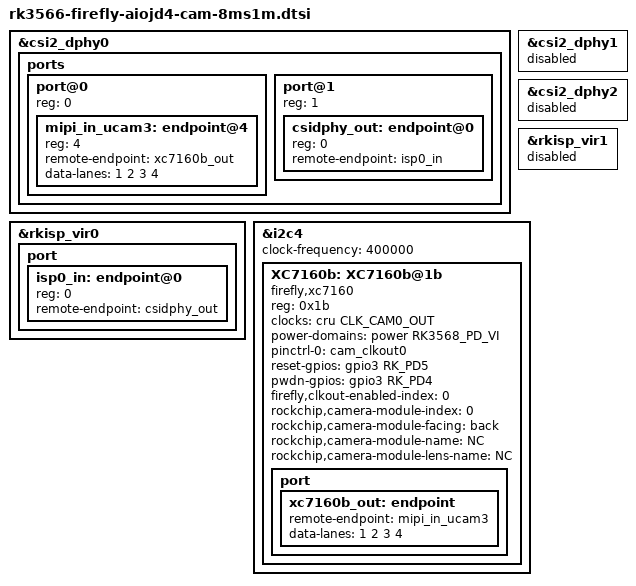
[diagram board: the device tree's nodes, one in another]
// SPDX-License-Identifier: (GPL-2.0+ OR MIT)
/*
 * Copyright (c) 2020 Rockchip Electronics Co., Ltd.
 *
 */

&csi2_dphy0 {
	status = "okay";

	ports {
		#address-cells = <1>;
		#size-cells = <0>;
		port@0 {
			reg = <0>;
			#address-cells = <1>;
			#size-cells = <0>;

			mipi_in_ucam3: endpoint@4 {
				reg = <4>;
				remote-endpoint = <&xc7160b_out>;
				data-lanes = <1 2 3 4>;
			};
		};
		port@1 {
			reg = <1>;
			#address-cells = <1>;
			#size-cells = <0>;

			csidphy_out: endpoint@0 {
				reg = <0>;
				remote-endpoint = <&isp0_in>;
			};
		};
	};
};

&csi2_dphy1 {
	status = "disabled";
};

&csi2_dphy2 {
	status = "disabled";
};

&rkisp_vir0 {
	status = "okay";

	port {
		#address-cells = <1>;
		#size-cells = <0>;

		isp0_in: endpoint@0 {
			reg = <0>;
			remote-endpoint = <&csidphy_out>;
		};
	};
};

&rkisp_vir1 {
	status = "disabled";
};

&i2c4 {
	status = "okay";
	clock-frequency = <400000>;

	XC7160b: XC7160b@1b{
        status = "okay";
        compatible = "firefly,xc7160";
        reg = <0x1b>;
        clocks = <&cru CLK_CAM0_OUT>;
        clock-names = "xvclk";
        //avdd-supply = <&vcc_mipi>;
        power-domains = <&power RK3568_PD_VI>;
        pinctrl-names = "default";
        pinctrl-0 = <&cam_clkout0>;

        //power-gpios = <&pca9555 PCA_IO0_4 GPIO_ACTIVE_HIGH>;
        reset-gpios = <&gpio3 RK_PD5 GPIO_ACTIVE_HIGH>;
        pwdn-gpios = <&gpio3 RK_PD4 GPIO_ACTIVE_HIGH>;

        firefly,clkout-enabled-index = <0>;
        rockchip,camera-module-index = <0>;
        rockchip,camera-module-facing = "back";
        rockchip,camera-module-name = "NC";
        rockchip,camera-module-lens-name = "NC";
        port {
			xc7160b_out: endpoint {
				remote-endpoint = <&mipi_in_ucam3>;
                data-lanes = <1 2 3 4>;
            };
        };
    };
};
